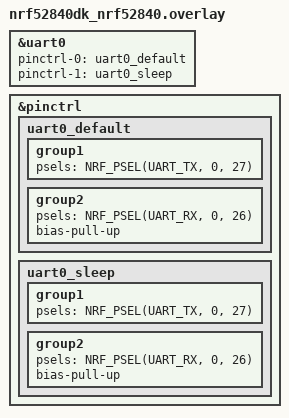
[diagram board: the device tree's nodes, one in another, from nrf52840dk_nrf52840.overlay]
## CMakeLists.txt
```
#
# Copyright (c) 2018 Nordic Semiconductor
#
# SPDX-License-Identifier: LicenseRef-Nordic-5-Clause
#
cmake_minimum_required(VERSION 3.20.0)

find_package(Zephyr REQUIRED HINTS $ENV{ZEPHYR_BASE})
project(NONE)

# NORDIC SDK APP START
target_sources(app PRIVATE src/main.c)
zephyr_include_directories(src)

# NORDIC SDK APP END
zephyr_library_include_directories(.)
```

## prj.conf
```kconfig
#
# Copyright (c) 2018 Nordic Semiconductor
#
# SPDX-License-Identifier: LicenseRef-Nordic-5-Clause
#

# Logger module
CONFIG_LOG=y

# Button and LED library
CONFIG_DK_LIBRARY=y

# Bluetooth LE
CONFIG_BT=y
CONFIG_BT_DEVICE_NAME="Score Board"

# Increase stack size for the main thread and System Workqueue
CONFIG_SYSTEM_WORKQUEUE_STACK_SIZE=2048
CONFIG_MAIN_STACK_SIZE=2048

# UART
CONFIG_SERIAL=y
CONFIG_UART_ASYNC_API=y
```

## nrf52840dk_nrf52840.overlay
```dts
// To get started, press Ctrl+Space to bring up the completion menu and view the available nodes.

// You can also use the buttons in the sidebar to perform actions on nodes.
// Actions currently available include:

// * Enabling / disabling the node
// * Adding the bus to a bus
// * Removing the node
// * Connecting ADC channels

// For more help, browse the DeviceTree documentation at https://docs.zephyrproject.org/latest/guides/dts/index.html
// You can also visit the nRF DeviceTree extension documentation at https://nrfconnect.github.io/vscode-nrf-connect/devicetree/nrfdevicetree.html

&uart0 {
    pinctrl-0 = <&uart0_default>;
    pinctrl-1 = <&uart0_sleep>;
    pinctrl-names = "default", "sleep";
};
   
&pinctrl {
    uart0_default: uart0_default {
        group1 {
            psels = <NRF_PSEL(UART_TX, 0, 27)>;
        };
        group2 {
            psels = <NRF_PSEL(UART_RX, 0, 26)>;
            bias-pull-up;
        };
    };
   
    uart0_sleep: uart0_sleep {
        group1 {
            psels = <NRF_PSEL(UART_TX, 0, 27)>;
        };
        group2 {
            psels = <NRF_PSEL(UART_RX, 0, 26)>;
            bias-pull-up;
        };
    };
};
```

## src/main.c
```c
/*
 * Copyright (c) 2023 Nordic Semiconductor ASA
 *
 * SPDX-License-Identifier: LicenseRef-Nordic-5-Clause
 */

#include <zephyr/kernel.h>
#include <zephyr/device.h>
#include <zephyr/devicetree.h>
#include <zephyr/logging/log.h>
#include <zephyr/bluetooth/bluetooth.h>
#include <zephyr/bluetooth/gap.h>
#include <dk_buttons_and_leds.h>
#include <zephyr/drivers/gpio.h>
#include <zephyr/sys/printk.h>
#include <string.h>
#include <zephyr/drivers/uart.h>
#include "df2301q.h"

#define COMPANY_ID_CODE 0x0059 // Nordic BLE ID

#define DEVICE_NAME CONFIG_BT_DEVICE_NAME
#define DEVICE_NAME_LEN (sizeof(DEVICE_NAME) - 1)

#define RUN_STATUS_LED DK_LED1
#define RUN_LED_BLINK_INTERVAL 1000

#define USER_BUTTON1 DK_BTN1_MSK
#define USER_BUTTON2 DK_BTN2_MSK

/* Define the size of the UART receive buffer */
#define RECEIVE_BUFF_SIZE 13

/* Define the receiving timeout period */
#define RECEIVE_TIMEOUT 1200

/* RTOS Task properties */
#define SB_STACKSIZE       1024
#define SB_PRIORITY        5 

/* Define semaphore */
K_SEM_DEFINE(sem, 0, 1);

/* Declare the structure for your custom data  */
typedef struct adv_mfg_data {
	uint16_t company_code; /* Company Identifier Code. */
	uint8_t team_home_points;
	uint8_t team_guest_points;
	uint8_t team_home_set;
	uint8_t team_guest_set;
	uint8_t serving; 
} adv_mfg_data_type;

/* Create an LE Advertising Parameters variable */
static struct bt_le_adv_param *adv_param = BT_LE_ADV_PARAM(BT_LE_ADV_OPT_NONE, /* No options specified */
											800, /* Min Advertising Interval 500ms (800*0.625ms) */
											801, /* Max Advertising Interval 500.625ms (801*0.625ms) */
											NULL); /* Set to NULL for undirected advertising */

/* Define and initialize a variable of type adv_mfg_data_type */
static adv_mfg_data_type adv_mfg_data = {COMPANY_ID_CODE, 0x00, 0x00, 0x00, 0x00, 0x00};

static unsigned char url_data[] = { };

LOG_MODULE_REGISTER(Scoreboard, LOG_LEVEL_INF);

static const struct bt_data ad[] = {
	BT_DATA_BYTES(BT_DATA_FLAGS, BT_LE_AD_NO_BREDR),
	BT_DATA(BT_DATA_NAME_COMPLETE, DEVICE_NAME, DEVICE_NAME_LEN),
	/* Include the Manufacturer Specific Data in the advertising packet. */
	BT_DATA(BT_DATA_MANUFACTURER_DATA, (unsigned char *)&adv_mfg_data, sizeof(adv_mfg_data)),
};

static const struct bt_data sd[] = {
	BT_DATA(BT_DATA_URI, url_data, sizeof(url_data)),
};

/* Get the device pointer of the UART hardware */
const struct device *uart= DEVICE_DT_GET(DT_NODELABEL(uart0));

/* Define the receive buffer */
static uint8_t rx_buf[RECEIVE_BUFF_SIZE] = {0};

uint8_t flag = 0;
static uint8_t DF2301Q_CMD = 0;

/* Define the callback function for UART */
static void uart_cb(const struct device *dev, struct uart_event *evt, void *user_data)
{
	switch (evt->type) {

	case UART_RX_RDY:

		uart_rx_disable(dev);

	    if(flag == 0)
		{
			dk_set_led(DK_LED3, 1);	
			flag = 1;
		}
		else if(flag == 1)
		{
			dk_set_led(DK_LED3, 0);
			flag = 0;
		}	

		if((evt->data.rx.len) == 13)
		{
			uart_rx_enable(dev ,rx_buf,sizeof rx_buf,RECEIVE_TIMEOUT);
			DF2301Q_CMD = 1;
			k_sem_give(&sem);

		}
		else if((evt->data.rx.len) == 12)
		{
			dk_set_led(DK_LED1, 0);
			dk_set_led(DK_LED2, 0);
			DF2301Q_CMD = 0;
		}

		uart_rx_enable(dev ,rx_buf,sizeof rx_buf,RECEIVE_TIMEOUT);
	
		k_sem_give(&sem);	
	break;

	case UART_RX_DISABLED:
		uart_rx_enable(dev ,rx_buf,sizeof rx_buf,RECEIVE_TIMEOUT);
	break;
		
	default:
	break;
	}
}

/* Add the definition of callback function and update the advertising data dynamically */
static void button_changed(uint32_t button_state, uint32_t has_changed)
{
	

}

/* Define the initialization function of the buttons and setup interrupt.  */
static int init_button(void)
{
	int err;

	err = dk_buttons_init(button_changed);
	if (err) {

	}

	return err;
}

int thread0(void)
{	
	int err;

	/* Setup leds on your board  */
	err = dk_leds_init();
	if (err) {		
		return -1;
	}	

	/* Setup buttons on your board  */
	err = init_button();
	if (err) {		
		return -1;
	}

	/* Verify that the UART device is ready */ 
	if (!device_is_ready(uart)){		
		return -1;
	}

	/* Register the UART callback function */
	err = uart_callback_set(uart, uart_cb, NULL);
	if (err) {
		return -1;
	}	

	/* Bluetooth enable */
	err = bt_enable(NULL);
	if (err) {		
		return -1;
	}	

	err = bt_le_adv_start(adv_param, ad, ARRAY_SIZE(ad), sd, ARRAY_SIZE(sd));
	if (err) {		
		return -1;
	}	

	err = uart_rx_enable(uart ,rx_buf, 13,RECEIVE_TIMEOUT);
	if (err) {			
		return -1;
	}	

	while(1)
	{		
		k_sem_take(&sem, K_FOREVER);
		if(DF2301Q_CMD == 1)
		{
			DF2301Q_CMD = 0;
			if((rx_buf[0] == 0xF4) && (rx_buf[1] == 0xF5))
			{			
				if(rx_buf[2] == 0x03)
				{				
					if(rx_buf[7] == TEAM_HOME_PLUS_ONE_POINT)	
					{
						if(adv_mfg_data.team_home_points == 99)
						{
							adv_mfg_data.team_home_points = 99;
						}
						else
						{
							adv_mfg_data.team_home_points += 1; 
						}
					}
					else if(rx_buf[7] == TEAM_HOME_MINUS_ONE_POINT)	
					{
						if(adv_mfg_data.team_home_points == 0)
						{
							adv_mfg_data.team_home_points = 0;
						}
						else
						{
							adv_mfg_data.team_home_points -= 1; 
						}
					}	
					else if(rx_buf[7] == TEAM_GUEST_PLUS_ONE_POINT)	
					{
						if(adv_mfg_data.team_guest_points == 99)
						{
							adv_mfg_data.team_guest_points = 99;
						}
						else
						{
							adv_mfg_data.team_guest_points += 1; 
						}
					}	
					else if(rx_buf[7] == TEAM_GUEST_MINUS_ONE_POINT)	
					{
						if(adv_mfg_data.team_guest_points == 0)
						{
							adv_mfg_data.team_guest_points = 0;
						}
						else
						{
							adv_mfg_data.team_guest_points -= 1; 
						}
					}	
					else if(rx_buf[7] == TEAM_HOME_PLUS_ONE_SET)	
					{
						if(adv_mfg_data.team_home_set == 9)
						{
							adv_mfg_data.team_home_set = 9;
						}
						else
						{
							adv_mfg_data.team_home_set += 1; 
						}
					}	
					else if(rx_buf[7] == TEAM_HOME_MINUS_ONE_SET)	
					{
						if(adv_mfg_data.team_home_set == 0)
						{
							adv_mfg_data.team_home_set = 0;
						}
						else
						{
							adv_mfg_data.team_home_set -= 1; 
						}
					}	
					else if(rx_buf[7] == TEAM_GUEST_PLUS_ONE_SET)	
					{
						if(adv_mfg_data.team_guest_set == 9)
						{
							adv_mfg_data.team_guest_set = 9;
						}
						else
						{
							adv_mfg_data.team_guest_set += 1; 
						}
					}	
					else if(rx_buf[7] == TEAM_GUEST_MINUS_ONE_SET)	
					{
						if(adv_mfg_data.team_guest_set == 0)
						{
							adv_mfg_data.team_guest_set = 0;
						}
						else
						{
							adv_mfg_data.team_guest_set -= 1; 
						}
					}
					else if(rx_buf[7] == TEAM_HOME_SERVING)	
					{
						adv_mfg_data.serving |= 1 << TEAM_HOME_SERVING_BIT;
						adv_mfg_data.serving &= ~(1 << TEAM_GUEST_SERVING_BIT);						
					}	
					else if(rx_buf[7] == TEAM_GUEST_SERVING)	
					{
						adv_mfg_data.serving |= 1 << TEAM_GUEST_SERVING_BIT;
						adv_mfg_data.serving &= ~(1 << TEAM_HOME_SERVING_BIT);	
					}
					else if(rx_buf[7] == SCORE_BOARD_RESET)	
					{
						adv_mfg_data.team_home_points = 0;
						adv_mfg_data.team_guest_points = 0;
						adv_mfg_data.team_home_set = 0;
						adv_mfg_data.team_guest_set = 0;
						adv_mfg_data.serving = 0;
					}
				}
				else if(rx_buf[2] == 0x02)
				{
					dk_set_led(DK_LED1, 0);
					dk_set_led(DK_LED2, 0);					
				}	

				bt_le_adv_update_data(ad, ARRAY_SIZE(ad), sd, ARRAY_SIZE(sd));
				memset(rx_buf, 0, sizeof(rx_buf));				
			}
			//k_sleep(K_MSEC(500));
		}		
	}
}


K_THREAD_DEFINE(thread0id, SB_STACKSIZE, thread0, NULL, NULL, NULL,
				SB_PRIORITY, 0, 0);
```

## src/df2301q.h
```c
/******************************************************************************
  * @file    df2301q.h
  * @author  Markel Robregado
  * @Date    May 8, 2024
  ******************************************************************************
  */

#ifndef DF2301Q_H_
#define DF2301Q_H_

#ifdef __cplusplus
 extern "C" {
#endif


/******************************************************************************/
/*************************** I2C REGISTER MAPPING  ****************************/
/******************************************************************************/
#define DF2301Q_I2C_ADDR                 0x64   //!< I2C address

#define DF2301Q_I2C_REG_CMDID            0x02   //!< Address of the register for requesting command word ID
#define DF2301Q_I2C_REG_PLAY_CMDID       0x03   //!< Address of the register for playing audio by command word ID
#define DF2301Q_I2C_REG_SET_MUTE         0x04   //!< Register for setting mute mode
#define DF2301Q_I2C_REG_SET_VOLUME       0x05   //!< Register for setting volume
#define DF2301Q_I2C_REG_WAKE_TIME        0x06   //!< Address of the register for wake-up time

/******************************************************************************/
/*************************** UART COMMUNICATION  ******************************/
/******************************************************************************/
#define DF2301Q_UART_BAUDRATE                       9600
#define DF2301Q_UART_MSG_DATA_MAX_SIZE              8            //!< Maximum data length of serial data frame
/*header*/
#define DF2301Q_UART_MSG_HEAD_LOW                   0xF4
#define DF2301Q_UART_MSG_HEAD_HIGH                  0xF5
#define DF2301Q_UART_MSG_HEAD                       ((DF2301Q_UART_MSG_HEAD_HIGH<<8)|DF2301Q_UART_MSG_HEAD_LOW)
/*tail*/
#define DF2301Q_UART_MSG_TAIL                       0xFB
/*msgType*/
#define DF2301Q_UART_MSG_TYPE_CMD_UP                0xA0
#define DF2301Q_UART_MSG_TYPE_CMD_DOWN              0xA1
#define DF2301Q_UART_MSG_TYPE_ACK                   0xA2
#define DF2301Q_UART_MSG_TYPE_NOTIFY                0xA3
/*msgCmd*/
#define DF2301Q_UART_MSG_CMD_ASR_RESULT             0x91         //Report voice recognition results
#define DF2301Q_UART_MSG_CMD_PLAY_VOICE             0x92         //Play local broadcast audio
#define DF2301Q_UART_MSG_CMD_GET_FLASHUID           0x93         //Read the serial number of FLASH
#define DF2301Q_UART_MSG_CMD_GET_VERSION            0x94         //Read version number
#define DF2301Q_UART_MSG_CMD_RESET_MODULE           0x95         //Reset the voice module
#define DF2301Q_UART_MSG_CMD_SET_CONFIG             0x96         //Settings
#define DF2301Q_UART_MSG_CMD_ENTER_OTA_MODE         0x97         //Enter update mode
#define DF2301Q_UART_MSG_CMD_NOTIFY_STATUS          0x9A         //Event notification
#define DF2301Q_UART_MSG_CMD_ACK_COMMON             0xAA
/* !!! if user want add please add form DF2301Q_UART_MSG_CMD_USER_START*/
#define DF2301Q_UART_MSG_CMD_USER_START             0xB0
/*msgData  msgCmd:DF2301Q_UART_MSG_CMD_PLAY_VOICE*/
#define DF2301Q_UART_MSG_DATA_PLAY_START            0x80
#define DF2301Q_UART_MSG_DATA_PLAY_PAUSE            0x81
#define DF2301Q_UART_MSG_DATA_PLAY_RESUME           0x82
#define DF2301Q_UART_MSG_DATA_PLAY_STOP             0x83
#define DF2301Q_UART_MSG_DATA_PLAY_BY_VOICEID       0x90
#define DF2301Q_UART_MSG_DATA_PLAY_BY_SEMANTIC_ID   0x91
#define DF2301Q_UART_MSG_DATA_PLAY_BY_CMD_ID        0x92
/*msgData  msg_cmd:DF2301Q_UART_MSG_CMD_GET_VERSION*/
#define DF2301Q_UART_MSG_DATA_VER_PROTOCOL          0x80         // Serial protocol version number
#define DF2301Q_UART_MSG_DATA_VER_SDK               0x81         // SDK version number
#define DF2301Q_UART_MSG_DATA_VER_ASR               0x82         // ASR component version number
#define DF2301Q_UART_MSG_DATA_VER_PREPROCESS        0x83         // Audio pre-processing algorithm version number
#define DF2301Q_UART_MSG_DATA_VER_PLAYER            0x84         // Player version number
#define DF2301Q_UART_MSG_DATA_VER_APP               0x8A         // App version number
/*msgData  msg_cmd:DF2301Q_UART_MSG_CMD_NOTIFY_STATUS*/
#define DF2301Q_UART_MSG_DATA_NOTIFY_POWERON        0xB0
#define DF2301Q_UART_MSG_DATA_NOTIFY_WAKEUPENTER    0xB1
#define DF2301Q_UART_MSG_DATA_NOTIFY_WAKEUPEXIT     0xB2
#define DF2301Q_UART_MSG_DATA_NOTIFY_PLAYSTART      0xB3
#define DF2301Q_UART_MSG_DATA_NOTIFY_PLAYEND        0xB4
/*msgData msg_cmd:DF2301Q_UART_MSG_CMD_SET_CONFIG*/
#define DF2301Q_UART_MSG_CMD_SET_VOLUME             0x80
#define DF2301Q_UART_MSG_CMD_SET_ENTERWAKEUP        0x81
#define DF2301Q_UART_MSG_CMD_SET_PRT_MID_RST        0x82
#define DF2301Q_UART_MSG_CMD_SET_MUTE               0x83
#define DF2301Q_UART_MSG_CMD_SET_WAKE_TIME          0x84
#define DF2301Q_UART_MSG_CMD_SET_NEEDACK            0x90
#define DF2301Q_UART_MSG_CMD_SET_NEEDSTRING         0x91
/*ACK error code*/
#define DF2301Q_UART_MSG_ACK_ERR_NONE               0x0
#define DF2301Q_UART_MSG_ACK_ERR_CHECKSUM           0xff
#define DF2301Q_UART_MSG_ACK_ERR_NOSUPPORT          0xfe

/******************************************************************************/
/*************************** COMMAND WORDS  ******************************/
/******************************************************************************/
#define TEAM_HOME_PLUS_ONE_POINT                    0x05
#define TEAM_HOME_MINUS_ONE_POINT                   0x06
#define TEAM_GUEST_PLUS_ONE_POINT                   0x07
#define TEAM_GUEST_MINUS_ONE_POINT                  0x08
#define TEAM_HOME_PLUS_ONE_SET                      0x09
#define TEAM_HOME_MINUS_ONE_SET                     0x0A
#define TEAM_GUEST_PLUS_ONE_SET                     0x0B
#define TEAM_GUEST_MINUS_ONE_SET                    0x0C
#define TEAM_HOME_SERVING                           0x0D 
#define TEAM_GUEST_SERVING                          0x0E 
#define SCORE_BOARD_RESET                           0x0F

#define TEAM_HOME_SERVING_BIT                       0  //1
#define TEAM_GUEST_SERVING_BIT                      1  //2


/**
* @struct sUartMsg_t
* @brief Serial data frame   struct
*/
typedef struct
{
    uint16_t header;
    uint16_t dataLength;
    uint8_t msgType;
    uint8_t msgCmd;
    uint8_t msgSeq;
    uint8_t msgData[DF2301Q_UART_MSG_DATA_MAX_SIZE];
    uint16_t chkSum;   /* send add auto */
    uint8_t tail;   /* send add auto */
}sUartMsg_t;

/**
* @enum eReceiveState_t
* @brief receive use state machine method, so two char can arrive different time
*/
typedef enum
{
    REV_STATE_HEAD0   = 0x00,
    REV_STATE_HEAD1   = 0x01,
    REV_STATE_LENGTH0 = 0x02,
    REV_STATE_LENGTH1 = 0x03,
    REV_STATE_TYPE    = 0x04,
    REV_STATE_CMD     = 0x05,
    REV_STATE_SEQ     = 0x06,
    REV_STATE_DATA    = 0x07,
    REV_STATE_CKSUM0  = 0x08,
    REV_STATE_CKSUM1  = 0x09,
    REV_STATE_TAIL    = 0x0a,
}eRecvState_t;


/**
  * @fn getCMDID
  * @brief Get the ID corresponding to the command word
  * @return Return the obtained command word ID, returning 0 means no valid ID is obtained
  */
uint8_t getCMDID(void);

 /**
  * @fn playByCMDID
  * @brief Play the corresponding reply audio according to the command word ID
  * @param play_id - Command word ID
  * @return None
  */
void playByCMDID(uint32_t play_id);

 /**
  * @fn resetModule
  * @brief Reset module
  * @return None
  */
void resetModule(void);

 /**
  * @fn settingCMD
  * @brief Set commands of the module
  * @param setType - Set type
  * @n       DF2301Q_UART_MSG_CMD_SET_VOLUME : Set volume, the set value range 1-7
  * @n       DF2301Q_UART_MSG_CMD_SET_ENTERWAKEUP : Enter wake-up state; set value 0
  * @n       DF2301Q_UART_MSG_CMD_SET_MUTE : Mute mode; set value 1: mute, 0: unmute
  * @n       DF2301Q_UART_MSG_CMD_SET_WAKE_TIME : Wake-up duration; the set value range 0-255s
  * @param setValue - Set value, refer to the set type above for the range
  * @return None
  */
void settingCMD(uint8_t setType, uint32_t setValue);

#ifdef __cplusplus
}
#endif

#endif /* DF2301Q_H_ */

 /*****END OF FILE****/
```
